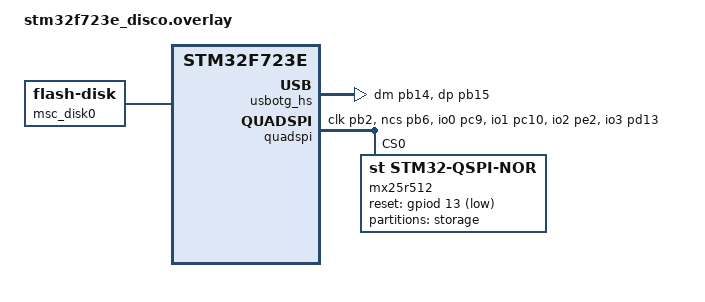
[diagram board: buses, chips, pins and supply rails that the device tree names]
 &usbotg_fs {
     status = "disabled";
 };

 &usbotg_hs {
     clocks = <&rcc STM32_CLOCK_BUS_AHB1 0x20000000>,
         <&rcc STM32_SRC_PLL_Q CK48M_SEL(0)>;
     pinctrl-0 = <&usb_otg_hs_dm_pb14 &usb_otg_hs_dp_pb15>;
     pinctrl-names = "default";
     num-bidir-endpoints = <4>;
     status = "ok";
 };


&quadspi {
	pinctrl-names = "default";
	pinctrl-0 = <&quadspi_clk_pb2 &quadspi_bk1_ncs_pb6
                &quadspi_bk1_io0_pc9 &quadspi_bk1_io1_pc10
                &quadspi_bk1_io2_pe2 &quadspi_bk1_io3_pd13>;
    flash-id = <1>;
    status = "okay";

	mx25r512: qspi-nor-flash@0 {
		compatible = "st,stm32-qspi-nor";
        reg = <0>;
        qspi-max-frequency = <80000000>;
        size = <DT_SIZE_M(512)>;
        reset-gpios = <&gpiod 13 GPIO_ACTIVE_LOW>;
        reset-gpios-duration = <10>;
        // working configuration for single wire SPI
        spi-bus-width = <1>;
        writeoc = "PP_1_1_4";
        // not working -> driver issue for four wire SPI
        // spi-bus-width = <4>;
        // writeoc = "PP_1_4_4";
        status = "okay";

        partitions {
            compatible = "fixed-partitions";
            #address-cells = <1>;
            #size-cells = <1>;
    
            storage_partition: partition@0 {
                label = "storage";
                reg = <0x00000000 DT_SIZE_M(1)>;
            };
        };
	};
};


/ {
	msc_disk0 {
		compatible = "zephyr,flash-disk";
		partition = <&storage_partition>;
		disk-name = "NAND";
		cache-size = <4096>;
	};
};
